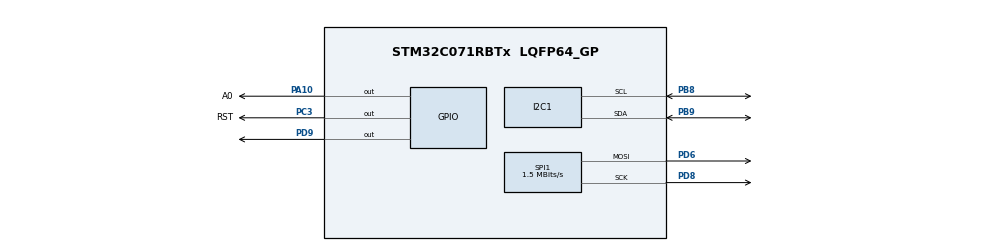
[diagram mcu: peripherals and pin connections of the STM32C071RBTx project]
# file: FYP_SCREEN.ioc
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I2C1.Timing=0x00402D41
Mcu.Family=STM32C0
Mcu.Name=STM32C071RBTx
Mcu.Package=LQFP64_GP
NUCLEO-C071RB.BUTTON=1
NUCLEO-C071RB.LD1=true
NUCLEO-C071RB.LD2=true
NUCLEO-C071RB.VCP=true
NVIC.EXTI4_15_IRQn=true\:0\:0\:false\:false\:true\:false\:true\:true
PA10.GPIO_Label=A0
PA10.Signal=GPIO_Output
PA2.Signal=USART2_TX
PA3.Signal=USART2_RX
PB8.Mode=I2C
PB8.Signal=I2C1_SCL
PB9.Mode=I2C
PB9.Signal=I2C1_SDA
PC3.GPIO_Label=RST
PC3.Signal=GPIO_Output
PD5.Signal=SPI1_MISO
PD6.Mode=TX_Only_Simplex_Unidirect_Master
PD6.Signal=SPI1_MOSI
PD8.Mode=TX_Only_Simplex_Unidirect_Master
PD8.Signal=SPI1_SCK
PD9.Signal=GPIO_Output
ProjectManager.HeapSize=0x200
ProjectManager.StackSize=0x400
ProjectManager.TargetToolchain=STM32CubeIDE
RCC.ADCFreq_Value=12000000
RCC.AHBFreq_Value=12000000
RCC.CortexFreq_Value=12000000
RCC.EXTERNAL_CLOCK_VALUE=12288000
RCC.HCLKFreq_Value=12000000
RCC.HSE_VALUE=8000000
RCC.HSI48_VALUE=48000000
RCC.HSI_VALUE=48000000
RCC.LSE_VALUE=32768
RCC.SYSCLKFreq_VALUE=12000000
SPI1.BaudRatePrescaler=SPI_BAUDRATEPRESCALER_8
SPI1.CLKPolarity=SPI_POLARITY_HIGH
SPI1.CalculateBaudRate=1.5 MBits/s
SPI1.DataSize=SPI_DATASIZE_8BIT
SPI1.Direction=SPI_DIRECTION_2LINES
SPI1.Mode=SPI_MODE_MASTER
SPI1.NSSPMode=SPI_NSS_PULSE_DISABLE
SPI1.VirtualType=VM_MASTER
VP_NUCLEO-C071RB_VS_BSP_COMMON.Mode=COMMON
board=NUCLEO-C071RB

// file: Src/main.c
/* USER CODE BEGIN Header */
/**
  ******************************************************************************
  * @file           : main.c
  * @brief          : Main program body
  ******************************************************************************
  * @attention
  *
  * Copyright (c) 2026 STMicroelectronics.
  * All rights reserved.
  *
  * This software is licensed under terms that can be found in the LICENSE file
  * in the root directory of this software component.
  * If no LICENSE file comes with this software, it is provided AS-IS.
  *
  ******************************************************************************
  */
/* USER CODE END Header */
#include "main.h"

/* USER CODE BEGIN Includes */
#include "lcd.h"
#include "i2c.h"
/* USER CODE END Includes */

COM_InitTypeDef BspCOMInit;

I2C_HandleTypeDef hi2c1;

SPI_HandleTypeDef hspi1;

void SystemClock_Config(void);
static void MX_GPIO_Init(void);
static void MX_SPI1_Init(void);
static void MX_I2C1_Init(void);

int main(void)
{

  /* MCU Configuration--------------------------------------------------------*/

  /* Reset of all peripherals, Initializes the Flash interface and the Systick. */
  HAL_Init();

  /* Configure the system clock */
  SystemClock_Config();

  /* Initialize all configured peripherals */
  MX_GPIO_Init();
  MX_SPI1_Init();
  MX_I2C1_Init();
  /* USER CODE BEGIN 2 */
  lcd_init(&hi2c1);

  lcd_put_cur(0, 0);
  lcd_send_string("Hello World");

  lcd_put_cur(1, 0);
  lcd_send_string("STM32 LCD");
  /* USER CODE END 2 */

  /* Initialize leds */
  BSP_LED_Init(LED_GREEN);
  BSP_LED_Init(LED_BLUE);

  /* Initialize USER push-button, will be used to trigger an interrupt each time it's pressed.*/
  BSP_PB_Init(BUTTON_USER, BUTTON_MODE_EXTI);

  /* Initialize COM1 port (115200, 8 bits (7-bit data + 1 stop bit), no parity */
  BspCOMInit.BaudRate   = 115200;
  BspCOMInit.WordLength = COM_WORDLENGTH_8B;
  BspCOMInit.StopBits   = COM_STOPBITS_1;
  BspCOMInit.Parity     = COM_PARITY_NONE;
  BspCOMInit.HwFlowCtl  = COM_HWCONTROL_NONE;
  if (BSP_COM_Init(COM1, &BspCOMInit) != BSP_ERROR_NONE)
  {
    Error_Handler();
  }

  /* Infinite loop */
  while (1)
  {

  }
}

void SystemClock_Config(void)
{
  RCC_OscInitTypeDef RCC_OscInitStruct = {0};
  RCC_ClkInitTypeDef RCC_ClkInitStruct = {0};

  __HAL_FLASH_SET_LATENCY(FLASH_LATENCY_0);

  /** Initializes the RCC Oscillators according to the specified parameters
  * in the RCC_OscInitTypeDef structure.
  */
  RCC_OscInitStruct.OscillatorType = RCC_OSCILLATORTYPE_HSI;
  RCC_OscInitStruct.HSIState = RCC_HSI_ON;
  RCC_OscInitStruct.HSIDiv = RCC_HSI_DIV4;
  RCC_OscInitStruct.HSICalibrationValue = RCC_HSICALIBRATION_DEFAULT;
  if (HAL_RCC_OscConfig(&RCC_OscInitStruct) != HAL_OK)
  {
    Error_Handler();
  }

  /** Initializes the CPU, AHB and APB buses clocks
  */
  RCC_ClkInitStruct.ClockType = RCC_CLOCKTYPE_HCLK|RCC_CLOCKTYPE_SYSCLK
                              |RCC_CLOCKTYPE_PCLK1;
  RCC_ClkInitStruct.SYSCLKSource = RCC_SYSCLKSOURCE_HSI;
  RCC_ClkInitStruct.SYSCLKDivider = RCC_SYSCLK_DIV1;
  RCC_ClkInitStruct.AHBCLKDivider = RCC_HCLK_DIV1;
  RCC_ClkInitStruct.APB1CLKDivider = RCC_APB1_DIV1;

  if (HAL_RCC_ClockConfig(&RCC_ClkInitStruct, FLASH_LATENCY_0) != HAL_OK)
  {
    Error_Handler();
  }
}

static void MX_I2C1_Init(void)
{

  hi2c1.Instance = I2C1;
  hi2c1.Init.Timing = 0x00402D41;
  hi2c1.Init.OwnAddress1 = 0;
  hi2c1.Init.AddressingMode = I2C_ADDRESSINGMODE_7BIT;
  hi2c1.Init.DualAddressMode = I2C_DUALADDRESS_DISABLE;
  hi2c1.Init.OwnAddress2 = 0;
  hi2c1.Init.OwnAddress2Masks = I2C_OA2_NOMASK;
  hi2c1.Init.GeneralCallMode = I2C_GENERALCALL_DISABLE;
  hi2c1.Init.NoStretchMode = I2C_NOSTRETCH_DISABLE;
  if (HAL_I2C_Init(&hi2c1) != HAL_OK)
  {
    Error_Handler();
  }

  /** Configure Analogue filter
  */
  if (HAL_I2CEx_ConfigAnalogFilter(&hi2c1, I2C_ANALOGFILTER_ENABLE) != HAL_OK)
  {
    Error_Handler();
  }

  /** Configure Digital filter
  */
  if (HAL_I2CEx_ConfigDigitalFilter(&hi2c1, 0) != HAL_OK)
  {
    Error_Handler();
  }

}

static void MX_SPI1_Init(void)
{

  /* SPI1 parameter configuration*/
  hspi1.Instance = SPI1;
  hspi1.Init.Mode = SPI_MODE_MASTER;
  hspi1.Init.Direction = SPI_DIRECTION_2LINES;
  hspi1.Init.DataSize = SPI_DATASIZE_8BIT;
  hspi1.Init.CLKPolarity = SPI_POLARITY_HIGH;
  hspi1.Init.CLKPhase = SPI_PHASE_1EDGE;
  hspi1.Init.NSS = SPI_NSS_SOFT;
  hspi1.Init.BaudRatePrescaler = SPI_BAUDRATEPRESCALER_8;
  hspi1.Init.FirstBit = SPI_FIRSTBIT_MSB;
  hspi1.Init.TIMode = SPI_TIMODE_DISABLE;
  hspi1.Init.CRCCalculation = SPI_CRCCALCULATION_DISABLE;
  hspi1.Init.CRCPolynomial = 7;
  hspi1.Init.CRCLength = SPI_CRC_LENGTH_DATASIZE;
  hspi1.Init.NSSPMode = SPI_NSS_PULSE_DISABLE;
  if (HAL_SPI_Init(&hspi1) != HAL_OK)
  {
    Error_Handler();
  }

}

static void MX_GPIO_Init(void)
{
  GPIO_InitTypeDef GPIO_InitStruct = {0};

  /* GPIO Ports Clock Enable */
  __HAL_RCC_GPIOC_CLK_ENABLE();
  __HAL_RCC_GPIOD_CLK_ENABLE();
  __HAL_RCC_GPIOA_CLK_ENABLE();
  __HAL_RCC_GPIOB_CLK_ENABLE();

  /*Configure GPIO pin Output Level */
  HAL_GPIO_WritePin(RST_GPIO_Port, RST_Pin, GPIO_PIN_RESET);

  /*Configure GPIO pin Output Level */
  HAL_GPIO_WritePin(GPIOD, GPIO_PIN_9, GPIO_PIN_RESET);

  /*Configure GPIO pin Output Level */
  HAL_GPIO_WritePin(A0_GPIO_Port, A0_Pin, GPIO_PIN_RESET);

  /*Configure GPIO pin : RST_Pin */
  GPIO_InitStruct.Pin = RST_Pin;
  GPIO_InitStruct.Mode = GPIO_MODE_OUTPUT_PP;
  GPIO_InitStruct.Pull = GPIO_NOPULL;
  GPIO_InitStruct.Speed = GPIO_SPEED_FREQ_LOW;
  HAL_GPIO_Init(RST_GPIO_Port, &GPIO_InitStruct);

  /*Configure GPIO pin : PD9 */
  GPIO_InitStruct.Pin = GPIO_PIN_9;
  GPIO_InitStruct.Mode = GPIO_MODE_OUTPUT_PP;
  GPIO_InitStruct.Pull = GPIO_NOPULL;
  GPIO_InitStruct.Speed = GPIO_SPEED_FREQ_LOW;
  HAL_GPIO_Init(GPIOD, &GPIO_InitStruct);

  /*Configure GPIO pin : A0_Pin */
  GPIO_InitStruct.Pin = A0_Pin;
  GPIO_InitStruct.Mode = GPIO_MODE_OUTPUT_PP;
  GPIO_InitStruct.Pull = GPIO_NOPULL;
  GPIO_InitStruct.Speed = GPIO_SPEED_FREQ_LOW;
  HAL_GPIO_Init(A0_GPIO_Port, &GPIO_InitStruct);

}

void Error_Handler(void)
{
  __disable_irq();
  while (1)
  {
  }
}
